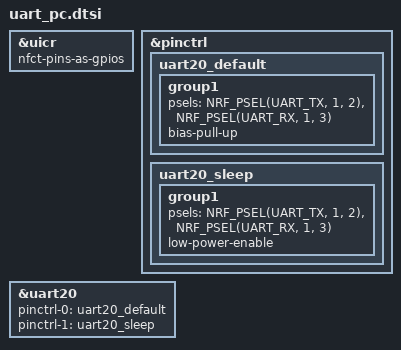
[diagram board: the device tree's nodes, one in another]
/*
 * The UART to the PC's USB bridge, shared by the app (app.overlay) and MCUboot's serial recovery
 * (sysbuild/mcuboot.overlay). Each sets its own current-speed.
 */

#include <zephyr/dt-bindings/pinctrl/nrf-pinctrl.h>

/* P1.02 and P1.03 are the NFC pins, they only work as GPIOs and the UART with this set */
&uicr {
	nfct-pins-as-gpios;
};

&pinctrl {
	/delete-node/ uart20_default;
	/delete-node/ uart20_sleep;

	uart20_default: uart20_default {
		group1 {
			psels = <NRF_PSEL(UART_TX, 1, 2)>,
				<NRF_PSEL(UART_RX, 1, 3)>;
			bias-pull-up;
		};
	};

	uart20_sleep: uart20_sleep {
		group1 {
			psels = <NRF_PSEL(UART_TX, 1, 2)>,
				<NRF_PSEL(UART_RX, 1, 3)>;
			low-power-enable;
		};
	};
};

&uart20 {
	status = "okay";
	pinctrl-0 = <&uart20_default>;
	pinctrl-1 = <&uart20_sleep>;
	pinctrl-names = "default", "sleep";
};
